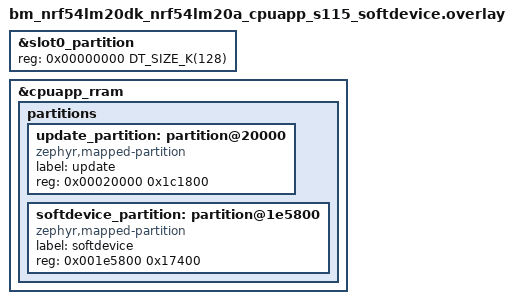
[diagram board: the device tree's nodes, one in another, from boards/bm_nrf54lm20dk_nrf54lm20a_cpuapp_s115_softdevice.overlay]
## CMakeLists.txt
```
#
# Copyright (c) 2026 Nordic Semiconductor ASA
#
# SPDX-License-Identifier: LicenseRef-Nordic-5-Clause
#

cmake_minimum_required(VERSION 3.20.0)

find_package(Zephyr REQUIRED HINTS $ENV{ZEPHYR_BASE})
project(ble_smp_updater)

target_sources(app PRIVATE
  src/main.c
  src/platform.c
  src/smp.c
  src/update.c
)
```

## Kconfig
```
#
# Copyright (c) 2026 Nordic Semiconductor ASA
#
# SPDX-License-Identifier: LicenseRef-Nordic-5-Clause
#

menu "BLE SMP updater sample"

module=SAMPLE_BLE_SMP_UPDATER
module-str=BLE SMP updater sample
source "$(ZEPHYR_BASE)/subsys/logging/Kconfig.template.log_config"

endmenu # "BLE SMP updater sample"

source "Kconfig.zephyr"
```

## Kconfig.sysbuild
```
#
# Copyright (c) 2026 Nordic Semiconductor ASA
#
# SPDX-License-Identifier: LicenseRef-Nordic-5-Clause
#

# The sample runs on S115 12.0.0-1.prototype, which it carries in softdevice/. This
# default comes before the SDK's, so it is the one that applies.
config SOFTDEVICE_FILE
	string
	default "$(APP_DIR)/softdevice/s115_nrf54lm20_12.0.0-1.prototype_softdevice.hex" if SOFTDEVICE_S115 && SOC_NRF54LM20A

source "share/sysbuild/Kconfig"
```

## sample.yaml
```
sample:
  name: Bluetooth LE SMP updater sample
tests:
  sample.ble_smp_updater:
    sysbuild: true
    build_only: true
    integration_platforms:
      - bm_nrf54lm20dk/nrf54lm20a/cpuapp/s115_softdevice
    platform_allow:
      - bm_nrf54lm20dk/nrf54lm20a/cpuapp/s115_softdevice
    tags: ci_build
```

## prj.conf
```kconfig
# Logging
CONFIG_LOG=y
CONFIG_LOG_BACKEND_BM_UARTE=y

# SoftDevice: the handler library forwards the stack's interrupts, runs its reset
# handler and hands SoC events to observers from the event interrupt. The sample
# enables the stack and polls BLE events itself.
CONFIG_SOFTDEVICE=y
CONFIG_NRF_SDH=y
CONFIG_NRF_SDH_DISPATCH_MODEL_IRQ=y
CONFIG_NRF_SDH_BLE=n
CONFIG_NRF_SDH_SOC_RAND_SEED=n

# Random seed for the stack
CONFIG_PSA_CRYPTO=y
CONFIG_PSA_WANT_GENERATE_RANDOM=y

CONFIG_REBOOT=y

# Link into the 128 kB code partition, below the update slot
CONFIG_USE_DT_CODE_PARTITION=y
```

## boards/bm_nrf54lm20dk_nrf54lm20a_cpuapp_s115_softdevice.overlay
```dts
/*
 * Copyright (c) 2026 Nordic Semiconductor ASA
 *
 * SPDX-License-Identifier: LicenseRef-Nordic-5-Clause
 */

/* The sample keeps the first 128 kB, and the rest up to the storage partition is the
 * slot it writes uploads into. S115 12.0.0-1.prototype sits at 0x1e5800.
 */

/delete-node/ &softdevice_partition;

&slot0_partition {
	reg = <0x00000000 DT_SIZE_K(128)>;
};

&cpuapp_rram {
	partitions {
		update_partition: partition@20000 {
			compatible = "zephyr,mapped-partition";
			label = "update";
			reg = <0x00020000 0x1c1800>;
		};

		softdevice_partition: partition@1e5800 {
			compatible = "zephyr,mapped-partition";
			label = "softdevice";
			reg = <0x001e5800 0x17400>;
		};
	};
};
```

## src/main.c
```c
/*
 * Copyright (c) 2026 Nordic Semiconductor ASA
 *
 * SPDX-License-Identifier: LicenseRef-Nordic-5-Clause
 */

/* BLE single-bank updater: serves SMP over an unencrypted BLE link and writes a plain
 * MCUboot image in place into the update slot. This file holds everything it asks of
 * the BLE stack, through the S115 SoftDevice API; the SMP server and the update
 * behind it see only SMP packets. It is the bare-metal form of IronSide DFU's BLE
 * alternate image, and keeps that image's BLE parameters.
 */

/*
 * Fixed parameters. They state what the BLE stack has to support, so a minimal
 * stack can be scoped from this list and the calls below.
 *
 * Link layer and GAP:
 * - Peripheral role only, one connection, one advertising set. 1M PHY only: a PHY
 *   update request is answered with 1M for both directions.
 * - Legacy connectable and scannable undirected advertising, every 100 ms on
 *   channels 37 to 39, with no timeout, filter policy "any": every central may
 *   connect. Advertising data: flags (LE General Discoverable, BR/EDR not
 *   supported) and the complete 128-bit SMP service UUID. Scan response: the
 *   complete local name "IronSide DFU", also the read-only GAP device name.
 * - The device address and the connection parameters are the stack's and the
 *   central's. No Peripheral Preferred Connection Parameters and no Central
 *   Address Resolution characteristic, no appearance.
 * - Connection event length 7.5 ms. Data length: the stack's maximum, on request.
 * - No security: pairing requests are refused with "pairing not supported", a
 *   request to encrypt with a stored key is answered with no key, and every
 *   attribute is open. Nothing is bonded or stored.
 *
 * GATT:
 * - ATT MTU 247. No Service Changed characteristic.
 * - One primary service 8D53DC1D-1DB7-4CD3-868B-8A527460AA84 with one
 *   characteristic DA2E7828-FBCE-4E01-AE9E-261174997C48: write without response
 *   and notify, value up to 244 bytes in this image's RAM, CCCD open. Two vendor
 *   UUID bases, an attribute table of 248 bytes, one queued notification.
 *
 * SMP transport:
 * - A request may span several ATT writes: they are joined until the length in the
 *   SMP header is in, up to SMP_REQ_MAX bytes. A request that outgrows it, or a
 *   write past its end, is dropped. One request in flight.
 * - Each response fits one notification.
 * - A disconnect ends the update session, so the host restarts the upload from
 *   offset 0. A reset command resets once its response is out.
 *
 * Stack placement and clocks:
 * - The stack sits at softdevice_partition and uses the RAM below the chosen
 *   zephyr,sram. It writes NVM for this image through sd_flash_write().
 * - BLE events are polled in thread mode; the stack's event interrupt only wakes
 *   the main loop for them.
 * - LF clock: the LFXO, 50 ppm. HFXO ramp-up 1500 us.
 */

#include <stdbool.h>
#include <stddef.h>
#include <stdint.h>
#include <string.h>

#include <zephyr/devicetree.h>
#include <zephyr/logging/log.h>
#include <zephyr/logging/log_ctrl.h>

#include <psa/crypto.h>

#include <ble.h>
#include <ble_gap.h>
#include <ble_gatts.h>
#include <ble_hci.h>
#include <nrf_error.h>
#include <nrf_sdm.h>
#include <nrf_soc.h>

#include <nrfx.h>

#include "platform.h"
#include "smp.h"
#include "update.h"

LOG_MODULE_REGISTER(app, CONFIG_SAMPLE_BLE_SMP_UPDATER_LOG_LEVEL);

#define ARRAY_LEN(a) (sizeof(a) / sizeof((a)[0]))

#define ATT_MTU	       247U
/* The largest SMP packet: one write-without-response or notification payload. */
#define SMP_PACKET_MAX (ATT_MTU - 3U)

#define ADV_INTERVAL_625US	 160U
#define CONN_EVENT_LENGTH_1250US 6U
#define ATTR_TAB_SIZE		 248U
/* The tag of the one connection configuration. BLE_CONN_CFG_TAG_DEFAULT names the
 * stack's defaults and cannot be configured. */
#define CONN_CFG_TAG		 1U
#define VS_UUID_COUNT		 2U
#define HFCLK_LATENCY_US	 1500U
#define HFINT_CALIBRATION_S	 4U

/* 16-bit aliases, octets 12 and 13 of each 128-bit UUID. */
#define SMP_SERVICE_UUID16 0xDC1DU
#define SMP_CHAR_UUID16	   0x7828U

/* 8D53DC1D-1DB7-4CD3-868B-8A527460AA84, little-endian. */
#define SMP_SERVICE_UUID_BYTES                                                                     \
	0x84U, 0xAAU, 0x60U, 0x74U, 0x52U, 0x8AU, 0x8BU, 0x86U, 0xD3U, 0x4CU, 0xB7U, 0x1DU, 0x1DU, \
		0xDCU, 0x53U, 0x8DU

/* DA2E7828-FBCE-4E01-AE9E-261174997C48, little-endian. */
#define SMP_CHAR_UUID_BYTES                                                                        \
	0x48U, 0x7CU, 0x99U, 0x74U, 0x11U, 0x26U, 0x9EU, 0xAEU, 0x01U, 0x4EU, 0xCEU, 0xFBU, 0x28U, \
		0x78U, 0x2EU, 0xDAU

#define DEVICE_NAME_LEN 12U
#define DEVICE_NAME	'I', 'r', 'o', 'n', 'S', 'i', 'd', 'e', ' ', 'D', 'F', 'U'

/* The APP_RAM_BASE this image gives the stack: its RAM ends below it. */
#define APP_RAM_BASE ((uint32_t)DT_REG_ADDR(DT_CHOSEN(zephyr_sram)))

#define SMP_HDR_LEN 8U

_Static_assert(SMP_PACKET_MAX <= BLE_GATTS_VAR_ATTR_LEN_MAX, "the SMP value outgrows an attribute");
_Static_assert(SMP_REQ_MAX <= (SMP_HDR_LEN + 0xFFFFU), "SMP_REQ_MAX outgrows the SMP length");

struct link {
	uint16_t conn_handle;
	uint8_t adv_handle;
	bool is_reset_requested;
	ble_gatts_char_handles_t smp;
};

static struct link link;

static union {
	ble_evt_t evt;
	uint8_t raw[BLE_EVT_LEN_MAX(ATT_MTU)];
} evt_buf;

static uint8_t smp_value[SMP_PACKET_MAX];
static uint8_t smp_rsp[SMP_PACKET_MAX];

/* The request the ATT writes so far have brought. */
static uint8_t smp_req[SMP_REQ_MAX];
static uint32_t smp_req_len;

/* The stack reads advertising data from RAM while it advertises. */
static uint8_t adv_data[] = {
	2U,
	BLE_GAP_AD_TYPE_FLAGS,
	BLE_GAP_ADV_FLAGS_LE_ONLY_GENERAL_DISC_MODE,
	17U,
	BLE_GAP_AD_TYPE_128BIT_SERVICE_UUID_COMPLETE,
	SMP_SERVICE_UUID_BYTES,
};
static uint8_t scan_rsp_data[] = {
	DEVICE_NAME_LEN + 1U,
	BLE_GAP_AD_TYPE_COMPLETE_LOCAL_NAME,
	DEVICE_NAME,
};

static const uint8_t device_name[DEVICE_NAME_LEN] = {DEVICE_NAME};

static const ble_uuid128_t smp_service_base = {{SMP_SERVICE_UUID_BYTES}};
static const ble_uuid128_t smp_char_base = {{SMP_CHAR_UUID_BYTES}};

static const ble_gap_adv_data_t adv = {
	.adv_data = {.p_data = adv_data, .len = sizeof(adv_data)},
	.scan_rsp_data = {.p_data = scan_rsp_data, .len = sizeof(scan_rsp_data)},
};

static const ble_gap_adv_params_t adv_params = {
	.properties = {.type = BLE_GAP_ADV_TYPE_CONNECTABLE_SCANNABLE_UNDIRECTED},
	.p_peer_addr = NULL,
	.interval = ADV_INTERVAL_625US,
	.duration = BLE_GAP_ADV_TIMEOUT_GENERAL_UNLIMITED,
	.filter_policy = BLE_GAP_ADV_FP_ANY,
	.primary_phy = BLE_GAP_PHY_1MBPS,
};

static const nrf_clock_lf_cfg_t lf_clock = {
	.source = NRF_CLOCK_LF_SRC_XTAL,
	.accuracy = NRF_CLOCK_LF_ACCURACY_50_PPM,
	.hfclk_latency = HFCLK_LATENCY_US,
	.hfint_ctiv = HFINT_CALIBRATION_S,
};

struct stack_cfg {
	uint32_t id;
	ble_cfg_t cfg;
};

/* Every configuration that differs from the stack's default. */
static const struct stack_cfg stack_cfgs[] = {
	{BLE_CONN_CFG_GAP,
	 {.conn_cfg = {.conn_cfg_tag = CONN_CFG_TAG,
		       .params.gap_conn_cfg = {.conn_count = 1U,
					       .event_length = CONN_EVENT_LENGTH_1250US}}}},
	{BLE_CONN_CFG_GATT,
	 {.conn_cfg = {.conn_cfg_tag = CONN_CFG_TAG,
		       .params.gatt_conn_cfg = {.att_mtu = ATT_MTU}}}},
	{BLE_COMMON_CFG_VS_UUID, {.common_cfg = {.vs_uuid_cfg = {.vs_uuid_count = VS_UUID_COUNT}}}},
	{BLE_GAP_CFG_PPCP_INCL_CONFIG,
	 {.gap_cfg = {.ppcp_include_cfg =
			      {.include_cfg = BLE_GAP_CHAR_INCL_CONFIG_EXCLUDE_WITHOUT_SPACE}}}},
	{BLE_GAP_CFG_CAR_INCL_CONFIG,
	 {.gap_cfg = {.car_include_cfg =
			      {.include_cfg = BLE_GAP_CHAR_INCL_CONFIG_EXCLUDE_WITHOUT_SPACE}}}},
	{BLE_GATTS_CFG_SERVICE_CHANGED,
	 {.gatts_cfg = {.service_changed = {.service_changed = 0U}}}},
	{BLE_GATTS_CFG_ATTR_TAB_SIZE,
	 {.gatts_cfg = {.attr_tab_size = {.attr_tab_size = ATTR_TAB_SIZE}}}},
};

static void stack_fault(uint32_t id, uint32_t pc, uint32_t info)
{
	(void)id;
	(void)pc;
	(void)info;
	platform_reset();
}

static bool smp_service_add(void)
{
	ble_uuid_t service = {.uuid = SMP_SERVICE_UUID16};
	ble_uuid_t chr = {.uuid = SMP_CHAR_UUID16};
	uint16_t service_handle = 0U;
	ble_gatts_char_md_t char_md = {.char_props = {.write_wo_resp = 1U, .notify = 1U}};
	ble_gatts_attr_md_t cccd_md = {.vloc = BLE_GATTS_VLOC_STACK};
	ble_gatts_attr_md_t value_md = {.vloc = BLE_GATTS_VLOC_USER, .vlen = 1U};

	BLE_GAP_CONN_SEC_MODE_SET_OPEN(&cccd_md.read_perm);
	BLE_GAP_CONN_SEC_MODE_SET_OPEN(&cccd_md.write_perm);
	BLE_GAP_CONN_SEC_MODE_SET_OPEN(&value_md.write_perm);
	char_md.p_cccd_md = &cccd_md;

	const ble_gatts_attr_t value = {
		.p_uuid = &chr,
		.p_attr_md = &value_md,
		.max_len = SMP_PACKET_MAX,
		.p_value = smp_value,
	};

	return (sd_ble_uuid_vs_add(&smp_service_base, &service.type) == NRF_SUCCESS) &&
	       (sd_ble_uuid_vs_add(&smp_char_base, &chr.type) == NRF_SUCCESS) &&
	       (sd_ble_gatts_service_add(BLE_GATTS_SRVC_TYPE_PRIMARY, &service, &service_handle) ==
		NRF_SUCCESS) &&
	       (sd_ble_gatts_characteristic_add(service_handle, &char_md, &value, &link.smp) ==
		NRF_SUCCESS);
}

/* Logs a stack call that failed. */
static bool is_stack_call_ok(uint32_t nrf_err, const char *call)
{
	if (nrf_err != NRF_SUCCESS) {
		LOG_ERR("%s failed, nrf_error %#x", call, nrf_err);
	}
	return nrf_err == NRF_SUCCESS;
}

static bool stack_enable(void)
{
	uint32_t required_ram_base = APP_RAM_BASE;
	ble_gap_conn_sec_mode_t name_perm;
	ble_version_t version;

	if (!is_stack_call_ok(sd_softdevice_enable(&lf_clock, stack_fault),
			      "sd_softdevice_enable")) {
		return false;
	}
	if (!platform_stack_seed()) {
		LOG_ERR("Seeding the stack failed");
		return false;
	}
	for (size_t i = 0U; i < ARRAY_LEN(stack_cfgs); i++) {
		if (!is_stack_call_ok(
			    sd_ble_cfg_set(stack_cfgs[i].id, &stack_cfgs[i].cfg, APP_RAM_BASE),
			    "sd_ble_cfg_set")) {
			LOG_ERR("Configuration %#x refused", stack_cfgs[i].id);
			return false;
		}
	}
	if (!is_stack_call_ok(sd_ble_enable(&required_ram_base), "sd_ble_enable")) {
		return false;
	}
	if (required_ram_base > APP_RAM_BASE) {
		LOG_ERR("The stack needs RAM up to %#x, the app starts at %#x", required_ram_base,
			APP_RAM_BASE);
		return false;
	}
	if (sd_ble_version_get(&version) == NRF_SUCCESS) {
		LOG_INF("SoftDevice firmware ID %#x, stack RAM up to %#x",
			version.subversion_number, required_ram_base);
	}

	BLE_GAP_CONN_SEC_MODE_SET_NO_ACCESS(&name_perm);
	link.adv_handle = BLE_GAP_ADV_SET_HANDLE_NOT_SET;

	if (!smp_service_add()) {
		LOG_ERR("Adding the SMP service failed");
		return false;
	}
	return is_stack_call_ok(
		       sd_ble_gap_device_name_set(&name_perm, device_name, sizeof(device_name)),
		       "sd_ble_gap_device_name_set") &&
	       is_stack_call_ok(sd_ble_gap_adv_set_configure(&link.adv_handle, &adv, &adv_params),
				"sd_ble_gap_adv_set_configure");
}

static void advertising_start(void)
{
	(void)sd_ble_gap_adv_start(link.adv_handle, CONN_CFG_TAG);
}

/* Hands a complete SMP request to the SMP server and notifies its response. A reset
 * waits for the notification to go out. */
static void smp_request_serve(const uint8_t *req, uint32_t len)
{
	bool is_reset = false;
	uint16_t rsp_len =
		(uint16_t)smp_packet_serve(req, len, smp_rsp, sizeof(smp_rsp), &is_reset);

	if (rsp_len == 0U) {
		return;
	}

	const ble_gatts_hvx_params_t hvx = {
		.handle = link.smp.value_handle,
		.type = BLE_GATT_HVX_NOTIFICATION,
		.offset = 0U,
		.p_len = &rsp_len,
		.p_data = smp_rsp,
	};

	link.is_reset_requested = is_reset;
	if (is_reset) {
		LOG_INF("Reset requested");
	}
	if ((sd_ble_gatts_hvx(link.conn_handle, &hvx) != NRF_SUCCESS) && is_reset) {
		platform_reset();
	}
}

/* Adds one ATT write to the request it continues, and serves the request once the
 * length in its SMP header is in. */
static void smp_write_join(const uint8_t *data, uint16_t len)
{
	if (len > (SMP_REQ_MAX - smp_req_len)) {
		smp_req_len = 0U;
		return;
	}
	memcpy(&smp_req[smp_req_len], data, len);
	smp_req_len += len;
	if (smp_req_len < SMP_HDR_LEN) {
		return;
	}

	const uint32_t req_len = SMP_HDR_LEN + (((uint32_t)smp_req[2] << 8) | smp_req[3]);

	if ((req_len > SMP_REQ_MAX) || (smp_req_len > req_len)) {
		smp_req_len = 0U;
		return;
	}
	if (smp_req_len == req_len) {
		smp_req_len = 0U;
		smp_request_serve(smp_req, req_len);
	}
}

/* Answers the requests the stack expects a reply to, and serves SMP writes. */
static void ble_event_serve(const ble_evt_t *evt)
{
	/* Every GAP and GATTS event starts with its connection handle. */
	const uint16_t conn = evt->evt.gap_evt.conn_handle;
	static const ble_gap_phys_t phys_1m = {.tx_phys = BLE_GAP_PHY_1MBPS,
					       .rx_phys = BLE_GAP_PHY_1MBPS};

	switch (evt->header.evt_id) {
	case BLE_GAP_EVT_CONNECTED:
		LOG_INF("Connected");
		link.conn_handle = conn;
		smp_req_len = 0U;
		(void)sd_ble_gatts_sys_attr_set(conn, NULL, 0U, 0U);
		break;
	case BLE_GAP_EVT_DISCONNECTED:
		LOG_INF("Disconnected, reason %#x", evt->evt.gap_evt.params.disconnected.reason);
		link.conn_handle = BLE_CONN_HANDLE_INVALID;
		smp_req_len = 0U;
		update_abort();
		if (link.is_reset_requested) {
			platform_reset();
		}
		advertising_start();
		break;
	case BLE_GAP_EVT_SEC_PARAMS_REQUEST:
		(void)sd_ble_gap_sec_params_reply(conn, BLE_GAP_SEC_STATUS_PAIRING_NOT_SUPP, NULL,
						  NULL);
		break;
	case BLE_GAP_EVT_SEC_INFO_REQUEST:
		(void)sd_ble_gap_sec_info_reply(conn, NULL);
		break;
	case BLE_GAP_EVT_PHY_UPDATE_REQUEST:
		(void)sd_ble_gap_phy_update(conn, &phys_1m);
		break;
	case BLE_GAP_EVT_DATA_LENGTH_UPDATE_REQUEST:
		(void)sd_ble_gap_data_length_update(conn, NULL, NULL);
		break;
	case BLE_GATTS_EVT_EXCHANGE_MTU_REQUEST:
		(void)sd_ble_gatts_exchange_mtu_reply(conn, ATT_MTU);
		break;
	case BLE_GATTS_EVT_SYS_ATTR_MISSING:
		(void)sd_ble_gatts_sys_attr_set(conn, NULL, 0U, 0U);
		break;
	case BLE_GATTS_EVT_WRITE:
		if (evt->evt.gatts_evt.params.write.handle == link.smp.value_handle) {
			smp_write_join(evt->evt.gatts_evt.params.write.data,
				       evt->evt.gatts_evt.params.write.len);
		}
		break;
	case BLE_GATTS_EVT_HVN_TX_COMPLETE:
		if (link.is_reset_requested) {
			platform_reset();
		}
		break;
	case BLE_GATTS_EVT_TIMEOUT:
		(void)sd_ble_gap_disconnect(conn, BLE_HCI_REMOTE_USER_TERMINATED_CONNECTION);
		break;
	default:
		/* An event that needs no reply. */
		break;
	}
}

/* Serves the BLE events the stack holds. Its SoC events go to the platform from the
 * event interrupt, which also wakes the main loop. */
static void stack_events_drain(void)
{
	for (;;) {
		uint16_t len = (uint16_t)sizeof(evt_buf);

		if (sd_ble_evt_get(evt_buf.raw, &len) != NRF_SUCCESS) {
			return;
		}
		ble_event_serve(&evt_buf.evt);
	}
}

int main(void)
{
	link.conn_handle = BLE_CONN_HANDLE_INVALID;

	const psa_status_t psa_status = psa_crypto_init();

	if (psa_status != PSA_SUCCESS) {
		LOG_ERR("psa_crypto_init failed, psa_status %d", psa_status);
	}
	if ((psa_status != PSA_SUCCESS) || !stack_enable()) {
		LOG_ERR("BLE stack bring-up failed");
		log_flush();
		platform_halt();
	}

	/* The stack has set the event interrupt's priority. */
	NVIC_EnableIRQ(SD_EVT_IRQn);
	advertising_start();
	LOG_INF("Advertising, update slot %#x, %u bytes", PLATFORM_SLOT_ADDR, PLATFORM_SLOT_SIZE);

	/* Logging is deferred: the main loop writes it out. */
	for (;;) {
		stack_events_drain();
		log_flush();
		__WFE();
	}
}
```

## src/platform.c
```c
/*
 * Copyright (c) 2026 Nordic Semiconductor ASA
 *
 * SPDX-License-Identifier: LicenseRef-Nordic-5-Clause
 */

/* The platform on sdk-nrf-bm. The SoftDevice handler library forwards the stack's
 * interrupts, runs its reset handler at system init, and hands SoC events to the
 * observer here from the stack's event interrupt. NVM writes go through
 * sd_flash_write(), which owns RRAMC while the stack is enabled.
 */

#include "platform.h"

#include <stdbool.h>
#include <stddef.h>
#include <stdint.h>
#include <string.h>

#include <zephyr/sys/reboot.h>

#include <psa/crypto.h>

#include <bm/softdevice_handler/nrf_sdh_soc.h>

#include <nrf_error.h>
#include <nrf_soc.h>

#include <nrfx.h>

#define RAND_SEED_LEN 32U
#define WORD_LEN      4U
/* The bytes one sd_flash_write() call writes at most. */
#define STAGE_LEN     256U

_Static_assert((STAGE_LEN % WORD_LEN) == 0U, "the stage holds whole words");
_Static_assert((PLATFORM_SLOT_ADDR % WORD_LEN) == 0U, "the update slot is word aligned");

enum flash_state {
	FLASH_IDLE,
	FLASH_BUSY,
	FLASH_FAILED,
};

static volatile enum flash_state flash_state;

/* sd_flash_write() reads the source until the write completes. */
static uint32_t stage[STAGE_LEN / WORD_LEN];

void platform_halt(void)
{
	for (;;) {
		__WFE();
	}
}

void platform_reset(void)
{
	sys_reboot(SYS_REBOOT_COLD);
	platform_halt();
}

void platform_secret_clear(uint8_t *buf, size_t len)
{
	volatile uint8_t *const p = buf;

	for (size_t i = 0U; i < len; i++) {
		p[i] = 0U;
	}
}

bool platform_stack_seed(void)
{
	uint8_t seed[RAND_SEED_LEN];
	const bool ok = (psa_generate_random(seed, sizeof(seed)) == PSA_SUCCESS) &&
			(sd_rand_seed_set(seed) == NRF_SUCCESS);

	platform_secret_clear(seed, sizeof(seed));
	return ok;
}

/* Serves one SoC event, in the stack's event interrupt. A seed request that cannot be
 * served stops the device, as a failed bring-up does. */
static void soc_event_serve(uint32_t evt, void *context)
{
	(void)context;

	switch (evt) {
	case NRF_EVT_RAND_SEED_REQUEST:
		if (!platform_stack_seed()) {
			platform_halt();
		}
		break;
	case NRF_EVT_FLASH_OPERATION_SUCCESS:
		flash_state = FLASH_IDLE;
		break;
	case NRF_EVT_FLASH_OPERATION_ERROR:
		flash_state = FLASH_FAILED;
		break;
	default:
		/* An event that needs no reply. */
		break;
	}
}

NRF_SDH_SOC_OBSERVER(soc_event_observer, soc_event_serve, NULL, USER);

/* Writes the whole words at @p word_addr from the stage, and waits for the stack to
 * report the write done. */
static bool stage_write(uint32_t word_addr, uint32_t word_count)
{
	flash_state = FLASH_BUSY;
	if (sd_flash_write((uint32_t *)(uintptr_t)word_addr, stage, word_count) != NRF_SUCCESS) {
		flash_state = FLASH_IDLE;
		return false;
	}
	/* The event interrupt ends the wait: its return sets the event register. */
	while (flash_state == FLASH_BUSY) {
		__WFE();
	}
	return flash_state == FLASH_IDLE;
}

bool platform_nvm_write(uint32_t addr, const uint8_t *data, uint32_t len)
{
	if ((addr < PLATFORM_SLOT_ADDR) || (len > PLATFORM_SLOT_SIZE) ||
	    ((addr - PLATFORM_SLOT_ADDR) > (PLATFORM_SLOT_SIZE - len))) {
		return false;
	}

	uint32_t word_addr = addr - (addr % WORD_LEN);
	uint32_t head = addr - word_addr;

	while (len > 0U) {
		uint32_t take = STAGE_LEN - head;

		if (take > len) {
			take = len;
		}

		const uint32_t span = head + take;
		const uint32_t word_count = (span + WORD_LEN - 1U) / WORD_LEN;

		/* RRAM needs no erase: the bytes around the range are written back as
		 * they are. */
		memcpy(stage, (const void *)(uintptr_t)word_addr, word_count * WORD_LEN);
		memcpy((uint8_t *)stage + head, data, take);
		if (!stage_write(word_addr, word_count)) {
			return false;
		}

		word_addr += word_count * WORD_LEN;
		data += take;
		len -= take;
		head = 0U;
	}
	return true;
}
```

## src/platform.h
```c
/*
 * Copyright (c) 2026 Nordic Semiconductor ASA
 *
 * SPDX-License-Identifier: LicenseRef-Nordic-5-Clause
 */

/* The sample's runtime platform: NVM writes through the BLE stack, its SoC events,
 * the update slot, and reset.
 */

#ifndef BLE_SMP_PLATFORM_H_
#define BLE_SMP_PLATFORM_H_

#include <stdbool.h>
#include <stddef.h>
#include <stdint.h>

#include <zephyr/devicetree.h>

/* The NVM the update writes, its start address and size in bytes. */
#define PLATFORM_SLOT_ADDR ((uint32_t)DT_REG_ADDR(DT_NODELABEL(update_partition)))
#define PLATFORM_SLOT_SIZE ((uint32_t)DT_REG_SIZE(DT_NODELABEL(update_partition)))

/* Stops. */
__attribute__((noreturn)) void platform_halt(void);

__attribute__((noreturn)) void platform_reset(void);

/* Clears sensitive data with stores the compiler keeps. */
void platform_secret_clear(uint8_t *buf, size_t len);

/* Gives the BLE stack a fresh random seed. The stack's later seed requests are
 * served from its event interrupt. */
bool platform_stack_seed(void);

/*
 * Writes @p len bytes to NVM at @p addr, which lies in the update slot, and returns
 * once the BLE stack has written them. Bytes before and after the range that share
 * its first and last word keep their value.
 */
bool platform_nvm_write(uint32_t addr, const uint8_t *data, uint32_t len);

#endif /* BLE_SMP_PLATFORM_H_ */
```

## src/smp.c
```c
/*
 * Copyright (c) 2026 Nordic Semiconductor ASA
 *
 * SPDX-License-Identifier: LicenseRef-Nordic-5-Clause
 */

/* The SMP server for the in-place update.
 *
 * Fixed parameters:
 * - Commands: MCUmgr parameters (0/6), bootloader information (0/8), reset (0/5),
 *   image state read (1/0) and image upload (1/1). Everything else is "not
 *   supported".
 * - Upload "image" 1, the update slot in place, only. The first chunk holds the whole
 *   MCUboot header.
 * - The image state lists the update slot as image 1, slot 0, when it holds a
 *   complete image: never active, confirmed or pending.
 * - Responses carry "rc", the SMP version 1 form. No image test, confirm or erase.
 */

#include "smp.h"

#include <stdbool.h>
#include <stdint.h>
#include <string.h>

#include "update.h"

#define SMP_HDR_LEN 8U
#define SMP_OP_MASK 0x07U

#define SMP_OP_READ  0U
#define SMP_OP_WRITE 2U

#define SMP_GROUP_OS	0U
#define SMP_GROUP_IMAGE 1U

#define SMP_ID_RESET	       5U
#define SMP_ID_MCUMGR_PARAMS   6U
#define SMP_ID_BOOTLOADER_INFO 8U
#define SMP_ID_IMAGE_STATE     0U
#define SMP_ID_UPLOAD	       1U

#define MGMT_ERR_EOK	  0U
#define MGMT_ERR_EUNKNOWN 1U
#define MGMT_ERR_EINVAL	  3U
#define MGMT_ERR_ENOTSUP  8U

/* The upload "image" that writes the update slot in place, and the slot the image
 * state reports it as. */
#define UPLOAD_IMAGE 1U
#define UPLOAD_SLOT  0U

/* The SMP requests the transport takes at a time. */
#define SMP_REQ_COUNT 1U

/* enum mcuboot_mode in MCUboot's bootutil/boot_status.h. */
#define MCUBOOT_MODE_FIRMWARE_LOADER 7U

#define CBOR_UINT   0U
#define CBOR_BSTR   2U
#define CBOR_TSTR   3U
#define CBOR_ARRAY  4U
#define CBOR_MAP    5U
#define CBOR_SIMPLE 7U
#define CBOR_FALSE  0xF4U
#define CBOR_TRUE   0xF5U

/* "255.255.65535.4294967295" */
#define VERSION_TEXT_MAX 24U

/* The fields of an SMP request this server reads. Absent unsigned fields are 0. */
struct smp_fields {
	uint32_t image;
	uint32_t off;
	uint32_t len;
	const uint8_t *data;
	uint32_t data_len;
	bool has_off;
	bool has_len;
	bool is_mode_query;
};

struct cbor_reader {
	const uint8_t *p;
	const uint8_t *end;
};

struct cbor_writer {
	uint8_t *p;
	const uint8_t *end;
};

static const char cbor_key_image[] = "image";
static const char cbor_key_off[] = "off";
static const char cbor_key_len[] = "len";
static const char cbor_key_data[] = "data";
static const char cbor_key_query[] = "query";
static const char cbor_key_rc[] = "rc";
static const char cbor_key_images[] = "images";
static const char cbor_key_slot[] = "slot";
static const char cbor_key_version[] = "version";
static const char cbor_key_hash[] = "hash";
static const char cbor_key_bootable[] = "bootable";
static const char cbor_key_pending[] = "pending";
static const char cbor_key_confirmed[] = "confirmed";
static const char cbor_key_active[] = "active";
static const char cbor_key_permanent[] = "permanent";
static const char cbor_key_buf_size[] = "buf_size";
static const char cbor_key_buf_count[] = "buf_count";
static const char cbor_key_bootloader[] = "bootloader";
static const char cbor_key_mode[] = "mode";
static const char cbor_key_no_downgrade[] = "no-downgrade";
static const char bootloader_name[] = "IronSide";

#define TEXT_LEN(text) ((uint32_t)sizeof(text) - 1U)

static uint32_t read_be16(const uint8_t *p)
{
	return ((uint32_t)p[0] << 8) | (uint32_t)p[1];
}

/* Integer arguments wider than 32 bits and indefinite lengths are refused. */
static bool cbor_head_read(struct cbor_reader *c, uint32_t *major, uint32_t *arg)
{
	if (c->p >= c->end) {
		return false;
	}

	const uint32_t initial = *c->p++;
	const uint32_t info = initial & 0x1FU;

	*major = initial >> 5;
	if (info < 24U) {
		*arg = info;
		return true;
	}
	if (info > 26U) {
		return false;
	}

	const uint32_t n = 1U << (info - 24U);

	if ((uint32_t)(c->end - c->p) < n) {
		return false;
	}
	*arg = 0U;
	for (uint32_t i = 0U; i < n; i++) {
		*arg = (*arg << 8) | *c->p++;
	}
	return true;
}

static bool cbor_string_read(struct cbor_reader *c, uint32_t major, const uint8_t **str,
			     uint32_t *len)
{
	uint32_t m = 0U;

	if (!cbor_head_read(c, &m, len) || (m != major) || ((uint32_t)(c->end - c->p) < *len)) {
		return false;
	}
	*str = c->p;
	c->p += *len;
	return true;
}

static bool cbor_head_write(struct cbor_writer *c, uint32_t major, uint32_t arg)
{
	uint32_t n = 4U;
	uint32_t info = 26U;

	if (arg < 24U) {
		n = 0U;
		info = arg;
	} else if (arg <= 0xFFU) {
		n = 1U;
		info = 24U;
	} else if (arg <= 0xFFFFU) {
		n = 2U;
		info = 25U;
	} else {
		/* Four argument bytes. */
	}

	if ((uint32_t)(c->end - c->p) < (1U + n)) {
		return false;
	}
	*c->p++ = (uint8_t)((major << 5) | info);
	for (uint32_t i = n; i > 0U; i--) {
		*c->p++ = (uint8_t)(arg >> (8U * (i - 1U)));
	}
	return true;
}

static bool cbor_text_write(struct cbor_writer *c, const char *text, uint32_t len)
{
	if (!cbor_head_write(c, CBOR_TSTR, len) || ((uint32_t)(c->end - c->p) < len)) {
		return false;
	}
	memcpy(c->p, text, len);
	c->p += len;
	return true;
}

static bool cbor_bytes_write(struct cbor_writer *c, const uint8_t *bytes, uint32_t len)
{
	if (!cbor_head_write(c, CBOR_BSTR, len) || ((uint32_t)(c->end - c->p) < len)) {
		return false;
	}
	memcpy(c->p, bytes, len);
	c->p += len;
	return true;
}

static bool cbor_bool_write(struct cbor_writer *c, bool value)
{
	if (c->p >= c->end) {
		return false;
	}
	*c->p++ = value ? CBOR_TRUE : CBOR_FALSE;
	return true;
}

static bool cbor_key_uint_write(struct cbor_writer *c, const char *key, uint32_t key_len,
				uint32_t value)
{
	return cbor_text_write(c, key, key_len) && cbor_head_write(c, CBOR_UINT, value);
}

static bool cbor_key_bool_write(struct cbor_writer *c, const char *key, uint32_t key_len,
				bool value)
{
	return cbor_text_write(c, key, key_len) && cbor_bool_write(c, value);
}

static bool is_key(const uint8_t *key, uint32_t key_len, const char *name, uint32_t name_len)
{
	return (key_len == name_len) && (memcmp(key, name, name_len) == 0);
}

/* Reads the request map. An empty payload reads as an empty map, as hosts send read
 * requests without one. Values under unknown keys are skipped when they are
 * integers, strings or simple values; nested items are refused. */
static bool smp_fields_read(struct cbor_reader *c, struct smp_fields *f)
{
	uint32_t major = 0U;
	uint32_t pairs = 0U;

	memset(f, 0, sizeof(*f));
	if (c->p == c->end) {
		return true;
	}
	if (!cbor_head_read(c, &major, &pairs) || (major != CBOR_MAP)) {
		return false;
	}

	for (uint32_t i = 0U; i < pairs; i++) {
		const uint8_t *key = NULL;
		const uint8_t *str = NULL;
		uint32_t key_len = 0U;
		uint32_t value = 0U;

		if (!cbor_string_read(c, CBOR_TSTR, &key, &key_len)) {
			return false;
		}

		const uint8_t *const value_start = c->p;

		if (!cbor_head_read(c, &major, &value)) {
			return false;
		}
		if ((major == CBOR_BSTR) || (major == CBOR_TSTR)) {
			c->p = value_start;
			if (!cbor_string_read(c, major, &str, &value)) {
				return false;
			}
		}

		if ((major == CBOR_UINT) &&
		    is_key(key, key_len, cbor_key_image, TEXT_LEN(cbor_key_image))) {
			f->image = value;
		} else if ((major == CBOR_UINT) &&
			   is_key(key, key_len, cbor_key_off, TEXT_LEN(cbor_key_off))) {
			f->off = value;
			f->has_off = true;
		} else if ((major == CBOR_UINT) &&
			   is_key(key, key_len, cbor_key_len, TEXT_LEN(cbor_key_len))) {
			f->len = value;
			f->has_len = true;
		} else if ((major == CBOR_BSTR) &&
			   is_key(key, key_len, cbor_key_data, TEXT_LEN(cbor_key_data))) {
			f->data = str;
			f->data_len = value;
		} else if ((major == CBOR_TSTR) &&
			   is_key(key, key_len, cbor_key_query, TEXT_LEN(cbor_key_query))) {
			f->is_mode_query =
				is_key(str, value, cbor_key_mode, TEXT_LEN(cbor_key_mode));
		} else if ((major > CBOR_TSTR) && (major != CBOR_SIMPLE)) {
			return false;
		} else {
			/* A value under a key this server ignores, such as "sha" or "upgrade". */
		}
	}
	return true;
}

static bool rc_write(struct cbor_writer *w, uint32_t rc)
{
	return cbor_head_write(w, CBOR_MAP, 1U) &&
	       cbor_text_write(w, cbor_key_rc, TEXT_LEN(cbor_key_rc)) &&
	       cbor_head_write(w, CBOR_UINT, rc);
}

static uint32_t upload_chunk_write(const struct smp_fields *f)
{
	if (!f->has_off || (f->data == NULL) || ((f->off == 0U) && !f->has_len)) {
		return MGMT_ERR_EINVAL;
	}
	if ((f->off == 0U) && (f->image != UPLOAD_IMAGE)) {
		return MGMT_ERR_ENOTSUP;
	}

	switch (update_write(f->off, f->len, f->data, f->data_len)) {
	case UPDATE_OK:
		return MGMT_ERR_EOK;
	case UPDATE_REFUSED:
		return MGMT_ERR_EINVAL;
	case UPDATE_WRITE_FAILED:
	default:
		return MGMT_ERR_EUNKNOWN;
	}
}

static bool upload_serve(const struct smp_fields *f, struct cbor_writer *w)
{
	const uint32_t rc = upload_chunk_write(f);

	return cbor_head_write(w, CBOR_MAP, 2U) &&
	       cbor_text_write(w, cbor_key_rc, TEXT_LEN(cbor_key_rc)) &&
	       cbor_head_write(w, CBOR_UINT, rc) &&
	       cbor_text_write(w, cbor_key_off, TEXT_LEN(cbor_key_off)) &&
	       cbor_head_write(w, CBOR_UINT, update_next_offset());
}

/* Writes "major.minor.revision", and ".build" when the build number is not 0, as
 * MCUmgr's image management does. */
static uint32_t version_text_write(const struct update_slot_info *info, char text[VERSION_TEXT_MAX])
{
	const uint32_t parts[] = {info->version_major, info->version_minor, info->version_revision,
				  info->version_build};
	const uint32_t part_count = (info->version_build != 0U) ? 4U : 3U;
	uint32_t len = 0U;

	for (uint32_t i = 0U; i < part_count; i++) {
		char digits[10];
		uint32_t digit_count = 0U;
		uint32_t value = parts[i];

		if (i != 0U) {
			text[len++] = '.';
		}
		do {
			digits[digit_count++] = (char)('0' + (value % 10U));
			value /= 10U;
		} while (value != 0U);
		while (digit_count > 0U) {
			text[len++] = digits[--digit_count];
		}
	}
	return len;
}

static bool image_state_serve(struct cbor_writer *w)
{
	struct update_slot_info info;
	char version[VERSION_TEXT_MAX];

	if (!update_slot_info_read(&info)) {
		return cbor_head_write(w, CBOR_MAP, 1U) &&
		       cbor_text_write(w, cbor_key_images, TEXT_LEN(cbor_key_images)) &&
		       cbor_head_write(w, CBOR_ARRAY, 0U);
	}

	const uint32_t version_len = version_text_write(&info, version);

	return cbor_head_write(w, CBOR_MAP, 1U) &&
	       cbor_text_write(w, cbor_key_images, TEXT_LEN(cbor_key_images)) &&
	       cbor_head_write(w, CBOR_ARRAY, 1U) && cbor_head_write(w, CBOR_MAP, 9U) &&
	       cbor_key_uint_write(w, cbor_key_image, TEXT_LEN(cbor_key_image), UPLOAD_IMAGE) &&
	       cbor_key_uint_write(w, cbor_key_slot, TEXT_LEN(cbor_key_slot), UPLOAD_SLOT) &&
	       cbor_text_write(w, cbor_key_version, TEXT_LEN(cbor_key_version)) &&
	       cbor_text_write(w, version, version_len) &&
	       cbor_text_write(w, cbor_key_hash, TEXT_LEN(cbor_key_hash)) &&
	       cbor_bytes_write(w, info.hash, UPDATE_HASH_LEN) &&
	       cbor_key_bool_write(w, cbor_key_bootable, TEXT_LEN(cbor_key_bootable), true) &&
	       cbor_key_bool_write(w, cbor_key_pending, TEXT_LEN(cbor_key_pending), false) &&
	       cbor_key_bool_write(w, cbor_key_confirmed, TEXT_LEN(cbor_key_confirmed), false) &&
	       cbor_key_bool_write(w, cbor_key_active, TEXT_LEN(cbor_key_active), false) &&
	       cbor_key_bool_write(w, cbor_key_permanent, TEXT_LEN(cbor_key_permanent), false);
}

static bool mcumgr_params_serve(struct cbor_writer *w)
{
	return cbor_head_write(w, CBOR_MAP, 2U) &&
	       cbor_key_uint_write(w, cbor_key_buf_size, TEXT_LEN(cbor_key_buf_size),
				   SMP_REQ_MAX) &&
	       cbor_key_uint_write(w, cbor_key_buf_count, TEXT_LEN(cbor_key_buf_count),
				   SMP_REQ_COUNT);
}

static bool bootloader_info_serve(const struct smp_fields *f, struct cbor_writer *w)
{
	if (f->is_mode_query) {
		return cbor_head_write(w, CBOR_MAP, 2U) &&
		       cbor_text_write(w, cbor_key_mode, TEXT_LEN(cbor_key_mode)) &&
		       cbor_head_write(w, CBOR_UINT, MCUBOOT_MODE_FIRMWARE_LOADER) &&
		       cbor_key_bool_write(w, cbor_key_no_downgrade,
					   TEXT_LEN(cbor_key_no_downgrade), true);
	}
	return cbor_head_write(w, CBOR_MAP, 1U) &&
	       cbor_text_write(w, cbor_key_bootloader, TEXT_LEN(cbor_key_bootloader)) &&
	       cbor_text_write(w, bootloader_name, TEXT_LEN(bootloader_name));
}

static bool smp_command_serve(uint32_t op, uint32_t group, uint32_t id, struct cbor_reader *req,
			      struct cbor_writer *w, bool *is_reset)
{
	struct smp_fields f;

	if (!smp_fields_read(req, &f)) {
		return rc_write(w, MGMT_ERR_EINVAL);
	}
	if ((op == SMP_OP_WRITE) && (group == SMP_GROUP_IMAGE) && (id == SMP_ID_UPLOAD)) {
		return upload_serve(&f, w);
	}
	if ((op == SMP_OP_READ) && (group == SMP_GROUP_IMAGE) && (id == SMP_ID_IMAGE_STATE)) {
		return image_state_serve(w);
	}
	if ((op == SMP_OP_READ) && (group == SMP_GROUP_OS) && (id == SMP_ID_MCUMGR_PARAMS)) {
		return mcumgr_params_serve(w);
	}
	if ((op == SMP_OP_READ) && (group == SMP_GROUP_OS) && (id == SMP_ID_BOOTLOADER_INFO)) {
		return bootloader_info_serve(&f, w);
	}
	if ((op == SMP_OP_WRITE) && (group == SMP_GROUP_OS) && (id == SMP_ID_RESET)) {
		*is_reset = true;
		return rc_write(w, MGMT_ERR_EOK);
	}
	return rc_write(w, MGMT_ERR_ENOTSUP);
}

uint32_t smp_packet_serve(const uint8_t *pkt, uint32_t len, uint8_t *rsp, uint32_t rsp_size,
			  bool *is_reset)
{
	*is_reset = false;
	if ((len < SMP_HDR_LEN) || (rsp_size < SMP_HDR_LEN) ||
	    (read_be16(&pkt[2]) != (len - SMP_HDR_LEN))) {
		return 0U;
	}

	const uint32_t op = pkt[0] & SMP_OP_MASK;
	struct cbor_reader req = {.p = &pkt[SMP_HDR_LEN], .end = &pkt[len]};
	struct cbor_writer w = {.p = &rsp[SMP_HDR_LEN], .end = &rsp[rsp_size]};

	if (!smp_command_serve(op, read_be16(&pkt[4]), pkt[7], &req, &w, is_reset)) {
		*is_reset = false;
		return 0U;
	}

	const uint32_t rsp_len = (uint32_t)(w.p - rsp);
	const uint32_t body_len = rsp_len - SMP_HDR_LEN;

	/* Read (0) and write (2) are answered with the next operation code. */
	memcpy(rsp, pkt, SMP_HDR_LEN);
	rsp[0] = (uint8_t)((pkt[0] & ~SMP_OP_MASK) | (op + 1U));
	rsp[2] = (uint8_t)(body_len >> 8);
	rsp[3] = (uint8_t)body_len;
	return rsp_len;
}
```

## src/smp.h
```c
/*
 * Copyright (c) 2026 Nordic Semiconductor ASA
 *
 * SPDX-License-Identifier: LicenseRef-Nordic-5-Clause
 */

/* The SMP server: one request packet in, one response packet out, with no transport
 * framing.
 */

#ifndef BLE_SMP_SMP_H_
#define BLE_SMP_SMP_H_

#include <stdbool.h>
#include <stdint.h>

/* The largest SMP request packet, header included, that the transport reassembles. */
#define SMP_REQ_MAX 1280U

/*
 * Serves the SMP packet @p pkt of @p len bytes, header included. Writes the response
 * packet into @p rsp and returns its length, or 0 when the request gets no response.
 * Sets @p is_reset when the request was the reset command, which the caller carries
 * out once the response has gone out.
 */
uint32_t smp_packet_serve(const uint8_t *pkt, uint32_t len, uint8_t *rsp, uint32_t rsp_size,
			  bool *is_reset);

#endif /* BLE_SMP_SMP_H_ */
```

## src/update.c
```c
/*
 * Copyright (c) 2026 Nordic Semiconductor ASA
 *
 * SPDX-License-Identifier: LicenseRef-Nordic-5-Clause
 */

/* The in-place update into the update slot.
 *
 * Fixed parameters:
 * - Only plain MCUboot images: an image with an encryption flag set is refused.
 * - No signature or hash check. The image is written as it arrives; the host checks
 *   it against the hash the image list reports.
 */

#include "update.h"

#include <stdbool.h>
#include <stddef.h>
#include <stdint.h>
#include <string.h>

#include "platform.h"

#define IMAGE_MAGIC		 0x96F3B83DUL
#define IMAGE_F_ENCRYPTED_AES128 0x04UL
#define IMAGE_F_ENCRYPTED_AES256 0x08UL
#define IMAGE_HEADER_LEN	 32U
#define TLV_INFO_MAGIC		 0x6907U
#define TLV_PROT_INFO_MAGIC	 0x6908U
#define TLV_INFO_LEN		 4U
#define TLV_HDR_LEN		 4U
#define TLV_SHA256		 0x10U

/* The upload into the update slot. */
struct session {
	bool is_uploading;
	uint32_t total;
	uint32_t next;
	uint32_t tlv_off;
};

/* The section bounds an MCUboot header gives. */
struct image_layout {
	uint32_t hdr_size;
	uint32_t img_size;
	uint32_t protect_tlv_size;
};

static struct session session;

static uint32_t read_le16(const uint8_t *p)
{
	return (uint32_t)p[0] | ((uint32_t)p[1] << 8);
}

static uint32_t read_le32(const uint8_t *p)
{
	return read_le16(p) | (read_le16(&p[2]) << 16);
}

void update_abort(void)
{
	session.is_uploading = false;
}

uint32_t update_next_offset(void)
{
	return session.next;
}

/* Reads the MCUboot header at @p hdr and checks that a plain image with this layout
 * fits @p total bytes. */
static bool header_read(const uint8_t *hdr, uint32_t total, struct image_layout *layout)
{
	layout->hdr_size = read_le16(&hdr[8]);
	layout->protect_tlv_size = read_le16(&hdr[10]);
	layout->img_size = read_le32(&hdr[12]);

	return (read_le32(&hdr[0]) == IMAGE_MAGIC) &&
	       ((read_le32(&hdr[16]) & (IMAGE_F_ENCRYPTED_AES128 | IMAGE_F_ENCRYPTED_AES256)) ==
		0U) &&
	       (layout->hdr_size >= IMAGE_HEADER_LEN) && (layout->img_size <= total) &&
	       ((total - layout->img_size) >=
		(layout->hdr_size + layout->protect_tlv_size + TLV_INFO_LEN));
}

/* Checks the header at the start of an upload and starts the session. The TLV info
 * the new image will hold is cleared first: until the last chunk writes it, the slot
 * reads as no image, whatever an earlier image left there. */
static enum update_status image_begin(uint32_t total, const uint8_t *data, uint32_t len)
{
	static const uint8_t no_tlv_info[TLV_INFO_LEN];
	struct image_layout layout;

	if ((total > PLATFORM_SLOT_SIZE) || (len < IMAGE_HEADER_LEN) ||
	    !header_read(data, total, &layout)) {
		return UPDATE_REFUSED;
	}

	session.tlv_off = layout.hdr_size + layout.img_size + layout.protect_tlv_size;
	if (!platform_nvm_write(PLATFORM_SLOT_ADDR + session.tlv_off, no_tlv_info,
				sizeof(no_tlv_info))) {
		return UPDATE_WRITE_FAILED;
	}
	session.total = total;
	session.next = 0U;
	session.is_uploading = true;
	return UPDATE_OK;
}

/*
 * Finds the TLV of @p type and @p len in the unprotected TLV area of the image at
 * @p image, which starts at @p tlv_off and ends by @p total. Returns its value, or
 * NULL when the area is malformed or holds no such TLV.
 */
static const uint8_t *tlv_find(const uint8_t *image, uint32_t tlv_off, uint32_t total,
			       uint32_t type, uint32_t len)
{
	if ((total < TLV_INFO_LEN) || (tlv_off > (total - TLV_INFO_LEN)) ||
	    (read_le16(&image[tlv_off]) != TLV_INFO_MAGIC)) {
		return NULL;
	}

	const uint32_t tlv_tot = read_le16(&image[tlv_off + 2U]);

	if ((tlv_tot < TLV_INFO_LEN) || (tlv_tot > (total - tlv_off))) {
		return NULL;
	}

	const uint32_t end = tlv_off + tlv_tot;
	uint32_t pos = tlv_off + TLV_INFO_LEN;

	while ((end - pos) >= TLV_HDR_LEN) {
		const uint32_t tlv_type = read_le16(&image[pos]);
		const uint32_t tlv_len = read_le16(&image[pos + 2U]);

		pos += TLV_HDR_LEN;
		if (tlv_len > (end - pos)) {
			return NULL;
		}
		if ((tlv_type == type) && (tlv_len == len)) {
			return &image[pos];
		}
		pos += tlv_len;
	}
	return NULL;
}

enum update_status update_write(uint32_t off, uint32_t total, const uint8_t *data, uint32_t len)
{
	if (off == 0U) {
		const enum update_status status = image_begin(total, data, len);

		if (status != UPDATE_OK) {
			update_abort();
			return status;
		}
	} else if (!session.is_uploading || (off != session.next)) {
		return UPDATE_OK;
	} else {
		/* The next chunk in order. */
	}

	if ((len > (session.total - session.next)) ||
	    !platform_nvm_write(PLATFORM_SLOT_ADDR + session.next, data, len)) {
		update_abort();
		return UPDATE_WRITE_FAILED;
	}
	session.next += len;

	if (session.next == session.total) {
		const uint8_t *const image = (const uint8_t *)(uintptr_t)PLATFORM_SLOT_ADDR;
		const bool has_tlvs = tlv_find(image, session.tlv_off, session.total, TLV_SHA256,
					       UPDATE_HASH_LEN) != NULL;

		update_abort();
		if (!has_tlvs) {
			return UPDATE_REFUSED;
		}
	}
	return UPDATE_OK;
}

bool update_slot_info_read(struct update_slot_info *info)
{
	const uint8_t *const image = (const uint8_t *)(uintptr_t)PLATFORM_SLOT_ADDR;
	struct image_layout layout;

	/* An upload in progress has not written its TLVs yet. */
	if (session.is_uploading || !header_read(image, PLATFORM_SLOT_SIZE, &layout)) {
		return false;
	}

	uint32_t tlv_off = layout.hdr_size + layout.img_size;

	/* The protected TLV area, when there is one, comes first. */
	if (layout.protect_tlv_size != 0U) {
		if (read_le16(&image[tlv_off]) != TLV_PROT_INFO_MAGIC) {
			return false;
		}
		tlv_off += layout.protect_tlv_size;
	}

	const uint8_t *const hash =
		tlv_find(image, tlv_off, PLATFORM_SLOT_SIZE, TLV_SHA256, UPDATE_HASH_LEN);

	if (hash == NULL) {
		return false;
	}

	info->version_major = image[20];
	info->version_minor = image[21];
	info->version_revision = (uint16_t)read_le16(&image[22]);
	info->version_build = read_le32(&image[24]);
	memcpy(info->hash, hash, UPDATE_HASH_LEN);
	return true;
}
```

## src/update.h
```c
/*
 * Copyright (c) 2026 Nordic Semiconductor ASA
 *
 * SPDX-License-Identifier: LicenseRef-Nordic-5-Clause
 */

/* The in-place update: a plain MCUboot image written into the update slot as it
 * arrives.
 */

#ifndef BLE_SMP_UPDATE_H_
#define BLE_SMP_UPDATE_H_

#include <stdbool.h>
#include <stdint.h>

/* The length of the image's SHA-256 hash TLV. */
#define UPDATE_HASH_LEN 32U

enum update_status {
	UPDATE_OK,
	/* The image does not fit the update slot, or is not a plain MCUboot image. */
	UPDATE_REFUSED,
	UPDATE_WRITE_FAILED,
};

/* The MCUboot image the update slot holds. */
struct update_slot_info {
	uint8_t version_major;
	uint8_t version_minor;
	uint16_t version_revision;
	uint32_t version_build;
	uint8_t hash[UPDATE_HASH_LEN];
};

/*
 * Writes @p len bytes of the image at offset @p off. Offset 0 starts the image,
 * @p total bytes long, and @p data then holds its whole header. A chunk at another
 * offset than update_next_offset() is ignored with UPDATE_OK, so the host resumes
 * there. The chunk that completes the image ends the session.
 */
enum update_status update_write(uint32_t off, uint32_t total, const uint8_t *data, uint32_t len);

uint32_t update_next_offset(void);

/* Ends the session. */
void update_abort(void);

/* Reads the version and hash of the image in the update slot. Returns false when
 * the slot holds no complete MCUboot image with a SHA-256 hash TLV. */
bool update_slot_info_read(struct update_slot_info *info);

#endif /* BLE_SMP_UPDATE_H_ */
```
